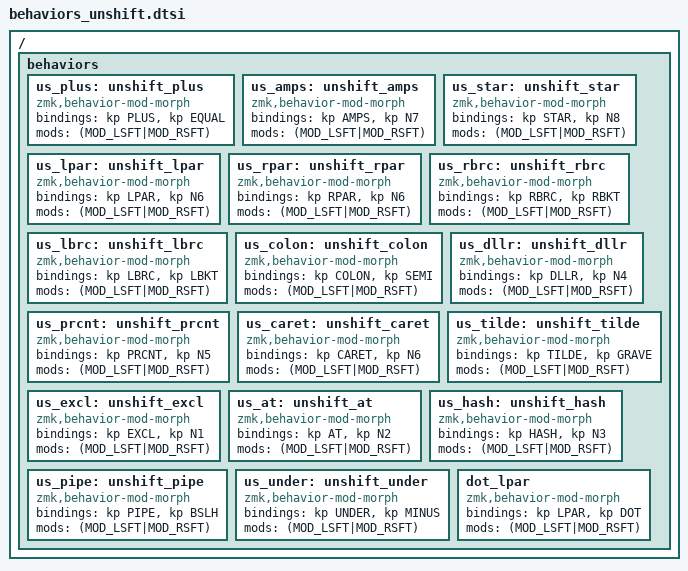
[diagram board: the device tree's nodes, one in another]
/ {
    behaviors {
        // Unshift -- most of these are to be able to run 
        /omit-if-no-ref/ us_plus: unshift_plus {
            compatible = "zmk,behavior-mod-morph";
            #binding-cells = <0>;
            bindings = <&kp PLUS>, <&kp EQUAL>;
            mods = <(MOD_LSFT|MOD_RSFT)>;
        };
        /omit-if-no-ref/ us_amps: unshift_amps {
            compatible = "zmk,behavior-mod-morph";
            #binding-cells = <0>;
            bindings = <&kp AMPS>, <&kp N7>;
            mods = <(MOD_LSFT|MOD_RSFT)>;
        }; 
        /omit-if-no-ref/ us_star: unshift_star {
            compatible = "zmk,behavior-mod-morph";
            #binding-cells = <0>;
            bindings = <&kp STAR>, <&kp N8>;
            mods = <(MOD_LSFT|MOD_RSFT)>;
        };
        /omit-if-no-ref/ us_lpar: unshift_lpar {
            compatible = "zmk,behavior-mod-morph";
            #binding-cells = <0>;
            bindings = <&kp LPAR>, <&kp N6>;
            mods = <(MOD_LSFT|MOD_RSFT)>;
        };
        /omit-if-no-ref/ us_rpar: unshift_rpar {
            compatible = "zmk,behavior-mod-morph";
            #binding-cells = <0>;
            bindings = <&kp RPAR>, <&kp N6>;
            mods = <(MOD_LSFT|MOD_RSFT)>;
        };
        /omit-if-no-ref/ us_rbrc: unshift_rbrc {
            compatible = "zmk,behavior-mod-morph";
            #binding-cells = <0>;
            bindings = <&kp RBRC>, <&kp RBKT>;
            mods = <(MOD_LSFT|MOD_RSFT)>;
        };
        /omit-if-no-ref/ us_lbrc: unshift_lbrc {
            compatible = "zmk,behavior-mod-morph";
            #binding-cells = <0>;
            bindings = <&kp LBRC>, <&kp LBKT>;
            mods = <(MOD_LSFT|MOD_RSFT)>;
        };
        /omit-if-no-ref/ us_colon: unshift_colon {
            compatible = "zmk,behavior-mod-morph";
            #binding-cells = <0>;
            bindings = <&kp COLON>, <&kp SEMI>;
            mods = <(MOD_LSFT|MOD_RSFT)>;
        };
        /omit-if-no-ref/ us_dllr: unshift_dllr {
            compatible = "zmk,behavior-mod-morph";
            #binding-cells = <0>;
            bindings = <&kp DLLR>, <&kp N4>;
            mods = <(MOD_LSFT|MOD_RSFT)>;
        };
        /omit-if-no-ref/ us_prcnt: unshift_prcnt {
            compatible = "zmk,behavior-mod-morph";
            #binding-cells = <0>;
            bindings = <&kp PRCNT>, <&kp N5>;
            mods = <(MOD_LSFT|MOD_RSFT)>;
        };
        /omit-if-no-ref/ us_caret: unshift_caret {
            compatible = "zmk,behavior-mod-morph";
            #binding-cells = <0>;
            bindings = <&kp CARET>, <&kp N6>;
            mods = <(MOD_LSFT|MOD_RSFT)>;
        };
        /omit-if-no-ref/ us_tilde: unshift_tilde {
            compatible = "zmk,behavior-mod-morph";
            #binding-cells = <0>;
            bindings = <&kp TILDE>, <&kp GRAVE>;
            mods = <(MOD_LSFT|MOD_RSFT)>;
        };
        /omit-if-no-ref/ us_excl: unshift_excl {
            compatible = "zmk,behavior-mod-morph";
            #binding-cells = <0>;
            bindings = <&kp EXCL>, <&kp N1>;
            mods = <(MOD_LSFT|MOD_RSFT)>;
        };
        /omit-if-no-ref/ us_at: unshift_at {
            compatible = "zmk,behavior-mod-morph";
            #binding-cells = <0>;
            bindings = <&kp AT>, <&kp N2>;
            mods = <(MOD_LSFT|MOD_RSFT)>;
        };
        /omit-if-no-ref/ us_hash: unshift_hash {
            compatible = "zmk,behavior-mod-morph";
            #binding-cells = <0>;
            bindings = <&kp HASH>, <&kp N3>;
            mods = <(MOD_LSFT|MOD_RSFT)>;
        };
        /omit-if-no-ref/ us_pipe: unshift_pipe {
            compatible = "zmk,behavior-mod-morph";
            #binding-cells = <0>;
            bindings = <&kp PIPE>, <&kp BSLH>;
            mods = <(MOD_LSFT|MOD_RSFT)>;
        };
        /omit-if-no-ref/ us_under: unshift_under {
            compatible = "zmk,behavior-mod-morph";
            #binding-cells = <0>;
            bindings = <&kp UNDER>, <&kp MINUS>;
            mods = <(MOD_LSFT|MOD_RSFT)>;
        };
		/omit-if-no-ref/ dot_lpar: dot_lpar {
			compatible = "zmk,behavior-mod-morph";
			#binding-cells = <0>;
			bindings = <&kp LPAR>, <&kp DOT>;
			mods = <(MOD_LSFT|MOD_RSFT)>;
		};
    };
};
